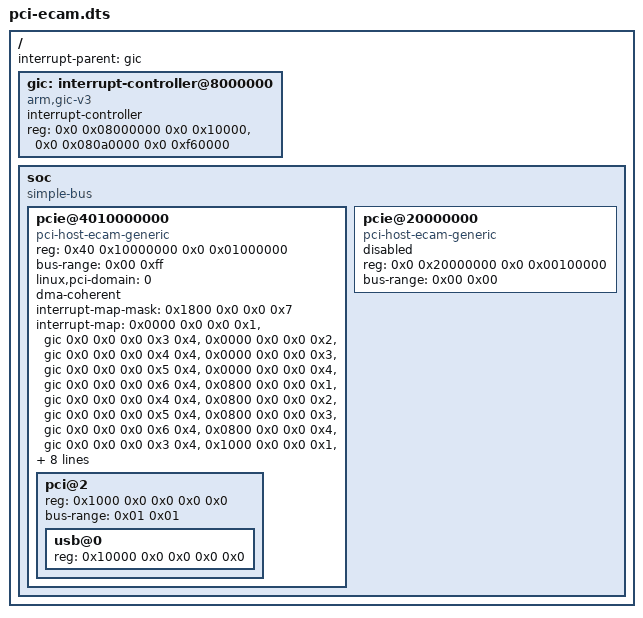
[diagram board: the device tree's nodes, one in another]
// SPDX-License-Identifier: MIT
// PCI core host-test fixture (tests/io/pci_core_test.c). Hand written after
// the QEMU 8.2 virt machine DT (qemu-system-aarch64 -machine
// virt,gic-version=3,dumpdtb=...): a pci-host-ecam-generic host whose
// interrupt-map follows the gpex swizzle (slot + pin - 1) % 4 onto GIC SPI
// 3..6, with a smaller ECAM window (16 buses), an I/O window, a 32-bit
// window and a 512 GiB 64-bit window (capped to 1 GiB by the core).
// Compiled by tests/io/pci.cmake with dtc.
/dts-v1/;

/ {
	#address-cells = <2>;
	#size-cells = <2>;
	interrupt-parent = <&gic>;

	gic: interrupt-controller@8000000 {
		compatible = "arm,gic-v3";
		#interrupt-cells = <3>;
		#address-cells = <2>;
		#size-cells = <2>;
		interrupt-controller;
		reg = <0x0 0x08000000 0x0 0x10000>, <0x0 0x080a0000 0x0 0xf60000>;
	};

	soc {
		compatible = "simple-bus";
		#address-cells = <2>;
		#size-cells = <2>;
		ranges;

		pcie@4010000000 {
			compatible = "pci-host-ecam-generic";
			device_type = "pci";
			reg = <0x40 0x10000000 0x0 0x01000000>;
			bus-range = <0x00 0xff>;
			linux,pci-domain = <0>;
			#address-cells = <3>;
			#size-cells = <2>;
			dma-coherent;
			ranges = <0x01000000 0x0 0x00000000 0x0 0x3eff0000 0x0 0x00010000>,
				 <0x02000000 0x0 0x10000000 0x0 0x10000000 0x0 0x2eff0000>,
				 <0x03000000 0x80 0x00000000 0x80 0x00000000 0x80 0x00000000>;
			#interrupt-cells = <1>;
			interrupt-map-mask = <0x1800 0x0 0x0 0x7>;
			interrupt-map =
				<0x0000 0x0 0x0 0x1 &gic 0x0 0x0 0x0 0x3 0x4>,
				<0x0000 0x0 0x0 0x2 &gic 0x0 0x0 0x0 0x4 0x4>,
				<0x0000 0x0 0x0 0x3 &gic 0x0 0x0 0x0 0x5 0x4>,
				<0x0000 0x0 0x0 0x4 &gic 0x0 0x0 0x0 0x6 0x4>,
				<0x0800 0x0 0x0 0x1 &gic 0x0 0x0 0x0 0x4 0x4>,
				<0x0800 0x0 0x0 0x2 &gic 0x0 0x0 0x0 0x5 0x4>,
				<0x0800 0x0 0x0 0x3 &gic 0x0 0x0 0x0 0x6 0x4>,
				<0x0800 0x0 0x0 0x4 &gic 0x0 0x0 0x0 0x3 0x4>,
				<0x1000 0x0 0x0 0x1 &gic 0x0 0x0 0x0 0x5 0x4>,
				<0x1000 0x0 0x0 0x2 &gic 0x0 0x0 0x0 0x6 0x4>,
				<0x1000 0x0 0x0 0x3 &gic 0x0 0x0 0x0 0x3 0x4>,
				<0x1000 0x0 0x0 0x4 &gic 0x0 0x0 0x0 0x4 0x4>,
				<0x1800 0x0 0x0 0x1 &gic 0x0 0x0 0x0 0x6 0x4>,
				<0x1800 0x0 0x0 0x2 &gic 0x0 0x0 0x0 0x3 0x4>,
				<0x1800 0x0 0x0 0x3 &gic 0x0 0x0 0x0 0x4 0x4>,
				<0x1800 0x0 0x0 0x4 &gic 0x0 0x0 0x0 0x5 0x4>;

			/* 00:02.0 bridge: a DT child, so 01:00.0 below gets a node. */
			pci@2 {
				device_type = "pci";
				reg = <0x1000 0x0 0x0 0x0 0x0>;
				bus-range = <0x01 0x01>;
				#address-cells = <3>;
				#size-cells = <2>;
				ranges;

				usb@0 {
					reg = <0x10000 0x0 0x0 0x0 0x0>;
				};
			};
		};

		pcie@20000000 {
			compatible = "pci-host-ecam-generic";
			device_type = "pci";
			reg = <0x0 0x20000000 0x0 0x00100000>;
			bus-range = <0x00 0x00>;
			ranges = <0x02000000 0x0 0x21000000 0x0 0x21000000 0x0 0x01000000>;
			status = "disabled";
			#address-cells = <3>;
			#size-cells = <2>;
		};
	};
};
